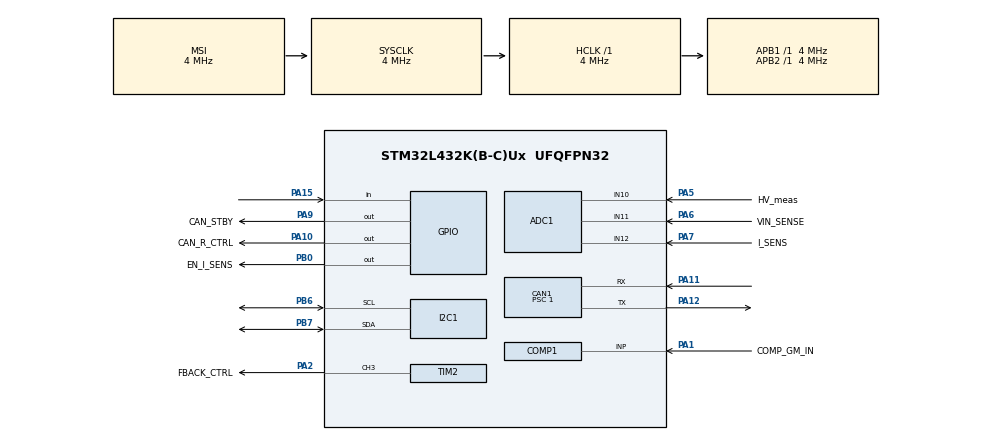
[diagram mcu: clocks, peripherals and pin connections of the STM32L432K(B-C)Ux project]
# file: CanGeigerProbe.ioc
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ADC1.Channel-0\#ChannelRegularConversion=ADC_CHANNEL_10
ADC1.Channel-1\#ChannelRegularConversion=ADC_CHANNEL_11
ADC1.Channel-2\#ChannelRegularConversion=ADC_CHANNEL_12
ADC1.Channel-3\#ChannelRegularConversion=ADC_CHANNEL_VREFINT
ADC1.Channel-4\#ChannelRegularConversion=ADC_CHANNEL_TEMPSENSOR
ADC1.NbrOfConversion=5
ADC1.NbrOfConversionFlag=1
ADC1.OffsetNumber-0\#ChannelRegularConversion=ADC_OFFSET_NONE
ADC1.OffsetNumber-1\#ChannelRegularConversion=ADC_OFFSET_NONE
ADC1.OffsetNumber-2\#ChannelRegularConversion=ADC_OFFSET_NONE
ADC1.OffsetNumber-3\#ChannelRegularConversion=ADC_OFFSET_NONE
ADC1.OffsetNumber-4\#ChannelRegularConversion=ADC_OFFSET_NONE
ADC1.OversamplingMode=ENABLE
ADC1.Rank-0\#ChannelRegularConversion=1
ADC1.Rank-1\#ChannelRegularConversion=2
ADC1.Rank-2\#ChannelRegularConversion=3
ADC1.Rank-3\#ChannelRegularConversion=4
ADC1.Rank-4\#ChannelRegularConversion=5
ADC1.Ratio=ADC_OVERSAMPLING_RATIO_16
ADC1.RightBitShift=ADC_RIGHTBITSHIFT_2
ADC1.SamplingTime-0\#ChannelRegularConversion=ADC_SAMPLETIME_247CYCLES_5
ADC1.SamplingTime-1\#ChannelRegularConversion=ADC_SAMPLETIME_640CYCLES_5
ADC1.SamplingTime-2\#ChannelRegularConversion=ADC_SAMPLETIME_247CYCLES_5
ADC1.SamplingTime-3\#ChannelRegularConversion=ADC_SAMPLETIME_640CYCLES_5
ADC1.SamplingTime-4\#ChannelRegularConversion=ADC_SAMPLETIME_640CYCLES_5
ADC1.master=1
CAN1.BS1=CAN_BS1_6TQ
CAN1.CalculateBaudRate=500000
CAN1.CalculateTimeBit=2000
CAN1.CalculateTimeQuantum=250.0
CAN1.NART=ENABLE
CAN1.Prescaler=1
CAN1.TXFP=ENABLE
COMP1.BlankingSrce=COMP_BLANKINGSRC_TIM2_OC3_COMP1
COMP1.Hysteresis=COMP_HYSTERESIS_MEDIUM
COMP1.Mode=COMP_POWERMODE_ULTRALOWPOWER
COMP1.OutputPol=COMP_OUTPUTPOL_INVERTED
Dma.ADC1.0.Direction=DMA_PERIPH_TO_MEMORY
Dma.ADC1.0.Instance=DMA1_Channel1
Dma.ADC1.0.MemDataAlignment=DMA_MDATAALIGN_HALFWORD
Dma.ADC1.0.MemInc=DMA_MINC_ENABLE
Dma.ADC1.0.Mode=DMA_NORMAL
Dma.ADC1.0.PeriphDataAlignment=DMA_PDATAALIGN_HALFWORD
Dma.ADC1.0.PeriphInc=DMA_PINC_DISABLE
Dma.ADC1.0.Priority=DMA_PRIORITY_LOW
Dma.I2C1_RX.3.Direction=DMA_PERIPH_TO_MEMORY
Dma.I2C1_RX.3.Instance=DMA1_Channel7
Dma.I2C1_RX.3.MemDataAlignment=DMA_MDATAALIGN_BYTE
Dma.I2C1_RX.3.MemInc=DMA_MINC_ENABLE
Dma.I2C1_RX.3.Mode=DMA_NORMAL
Dma.I2C1_RX.3.PeriphDataAlignment=DMA_PDATAALIGN_BYTE
Dma.I2C1_RX.3.PeriphInc=DMA_PINC_DISABLE
Dma.I2C1_RX.3.Priority=DMA_PRIORITY_LOW
Dma.I2C1_TX.2.Direction=DMA_MEMORY_TO_PERIPH
Dma.I2C1_TX.2.Instance=DMA1_Channel6
Dma.I2C1_TX.2.MemDataAlignment=DMA_MDATAALIGN_BYTE
Dma.I2C1_TX.2.MemInc=DMA_MINC_ENABLE
Dma.I2C1_TX.2.Mode=DMA_NORMAL
Dma.I2C1_TX.2.PeriphDataAlignment=DMA_PDATAALIGN_BYTE
Dma.I2C1_TX.2.PeriphInc=DMA_PINC_DISABLE
Dma.I2C1_TX.2.Priority=DMA_PRIORITY_LOW
Dma.Request0=ADC1
Dma.Request1=TIM2_UP
Dma.Request2=I2C1_TX
Dma.Request3=I2C1_RX
Dma.TIM2_UP.1.Direction=DMA_MEMORY_TO_PERIPH
Dma.TIM2_UP.1.Instance=DMA1_Channel2
Dma.TIM2_UP.1.MemDataAlignment=DMA_MDATAALIGN_WORD
Dma.TIM2_UP.1.MemInc=DMA_MINC_ENABLE
Dma.TIM2_UP.1.Mode=DMA_NORMAL
Dma.TIM2_UP.1.PeriphDataAlignment=DMA_PDATAALIGN_WORD
Dma.TIM2_UP.1.PeriphInc=DMA_PINC_DISABLE
Dma.TIM2_UP.1.Priority=DMA_PRIORITY_LOW
I2C1.Timing=0x00100D14
Mcu.Family=STM32L4
Mcu.Name=STM32L432K(B-C)Ux
Mcu.Package=UFQFPN32
NVIC.CAN1_RX0_IRQn=true\:0\:0\:false\:false\:true\:true\:true\:true
NVIC.CAN1_TX_IRQn=true\:0\:0\:false\:false\:true\:true\:true\:true
NVIC.DMA1_Channel1_IRQn=true\:0\:0\:false\:false\:true\:false\:true\:true
NVIC.DMA1_Channel2_IRQn=true\:0\:0\:false\:false\:true\:false\:true\:true
NVIC.DMA1_Channel6_IRQn=true\:0\:0\:false\:false\:true\:false\:true\:true
NVIC.DMA1_Channel7_IRQn=true\:0\:0\:false\:false\:true\:false\:true\:true
NVIC.I2C1_ER_IRQn=true\:0\:0\:false\:false\:true\:true\:true\:true
NVIC.I2C1_EV_IRQn=true\:0\:0\:false\:false\:true\:true\:true\:true
NVIC.LPTIM1_IRQn=true\:0\:0\:false\:false\:true\:true\:true\:true
NVIC.PriorityGroup=NVIC_PRIORITYGROUP_4
PA1.GPIO_Label=COMP_GM_IN
PA1.Mode=INP
PA1.Signal=COMP1_INP
PA10.GPIO_Label=CAN_R_CTRL
PA10.Signal=GPIO_Output
PA11.Mode=CAN_Activate
PA11.Signal=CAN1_RX
PA12.Mode=CAN_Activate
PA12.Signal=CAN1_TX
PA13\ (JTMS-SWDIO).GPIO_Label=SWDIO
PA13\ (JTMS-SWDIO).Mode=Trace_Asynchronous_SW
PA13\ (JTMS-SWDIO).Signal=SYS_JTMS-SWDIO
PA14\ (JTCK-SWCLK).GPIO_Label=SWCLK
PA14\ (JTCK-SWCLK).Mode=Trace_Asynchronous_SW
PA14\ (JTCK-SWCLK).Signal=SYS_JTCK-SWCLK
PA15\ (JTDI).Signal=GPIO_Input
PA2.GPIO_Label=FBACK_CTRL
PA2.GPIO_PuPd=GPIO_PULLDOWN
PA2.Signal=S_TIM2_CH3
PA5.GPIO_Label=HV_meas
PA5.Signal=ADCx_IN10
PA6.GPIO_Label=VIN_SENSE
PA6.Signal=ADCx_IN11
PA7.GPIO_Label=I_SENS
PA7.Signal=ADCx_IN12
PA9.GPIO_Label=CAN_STBY
PA9.Signal=GPIO_Output
PB0.GPIO_Label=EN_I_SENS
PB0.Signal=GPIO_Output
PB3\ (JTDO-TRACESWO).GPIO_Label=SWO
PB3\ (JTDO-TRACESWO).Mode=Trace_Asynchronous_SW
PB3\ (JTDO-TRACESWO).Signal=SYS_JTDO-SWO
PB6.Mode=I2C
PB6.Signal=I2C1_SCL
PB7.Mode=I2C
PB7.Signal=I2C1_SDA
ProjectManager.HeapSize=0x200
ProjectManager.StackSize=0x400
ProjectManager.TargetToolchain=STM32CubeIDE
RCC.ADCCLockSelection=RCC_ADCCLKSOURCE_SYSCLK
RCC.ADCFreq_Value=4000000
RCC.AHBFreq_Value=4000000
RCC.APB1Freq_Value=4000000
RCC.APB1TimFreq_Value=4000000
RCC.APB2Freq_Value=4000000
RCC.APB2TimFreq_Value=4000000
RCC.CortexFreq_Value=4000000
RCC.HCLKFreq_Value=4000000
RCC.HSE_VALUE=8000000
RCC.HSI48_VALUE=48000000
RCC.HSI_VALUE=16000000
RCC.LSE_VALUE=32768
RCC.MSI_VALUE=4000000
RCC.PLLSourceVirtual=RCC_PLLSOURCE_HSI
RCC.PWR_Regulator_Voltage_Scale=PWR_REGULATOR_VOLTAGE_SCALE2
RCC.SYSCLKFreq_VALUE=4000000
RCC.USBFreq_Value=64000000
RCC.VCOOutputFreq_Value=128000000
SH.ADCx_IN10.0=ADC1_IN10,IN10-Single-Ended
SH.ADCx_IN11.0=ADC1_IN11,IN11-Single-Ended
SH.ADCx_IN12.0=ADC1_IN12,IN12-Single-Ended
SH.S_TIM2_CH3.0=TIM2_CH3,PWM Generation3 CH3
TIM2.AutoReloadPreload=TIM_AUTORELOAD_PRELOAD_ENABLE
TIM2.Channel-PWM\ Generation3\ CH3=TIM_CHANNEL_3
VP_ADC1_TempSens_Input.Mode=IN-TempSens
VP_ADC1_Vref_Input.Mode=IN-Vrefint
VP_COMP1_VS_DACOUT1.Mode=INM_DACOUT1
VP_DAC1_VS_DACI1.Mode=DAC_OUT1_Int
VP_LPTIM1_VS_LPTIM_counterModeInternalClock.Mode=Counts__internal_clock_event_00
VP_TIM2_VS_ClockSourceINT.Mode=Internal
board=custom

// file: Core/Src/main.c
/* USER CODE BEGIN Header */
/**
  ******************************************************************************
  * @file           : main.c
  * @brief          : Main program body
  ******************************************************************************
  * @attention
  *
  * Copyright (c) 2026 STMicroelectronics.
  * All rights reserved.
  *
  * This software is licensed under terms that can be found in the LICENSE file
  * in the root directory of this software component.
  * If no LICENSE file comes with this software, it is provided AS-IS.
  *
  ******************************************************************************
  */
/* USER CODE END Header */
#include "main.h"

ADC_HandleTypeDef hadc1;
DMA_HandleTypeDef hdma_adc1;

CAN_HandleTypeDef hcan1;

COMP_HandleTypeDef hcomp1;

DAC_HandleTypeDef hdac1;

I2C_HandleTypeDef hi2c1;
DMA_HandleTypeDef hdma_i2c1_tx;
DMA_HandleTypeDef hdma_i2c1_rx;

LPTIM_HandleTypeDef hlptim1;

TIM_HandleTypeDef htim2;
DMA_HandleTypeDef hdma_tim2_up;

void SystemClock_Config(void);
static void MX_GPIO_Init(void);
static void MX_DMA_Init(void);
static void MX_ADC1_Init(void);
static void MX_CAN1_Init(void);
static void MX_COMP1_Init(void);
static void MX_DAC1_Init(void);
static void MX_I2C1_Init(void);
static void MX_TIM2_Init(void);
static void MX_LPTIM1_Init(void);

int main(void)
{

  /* USER CODE BEGIN 1 */
  /* Aplikacja jest zrelokowana za bootloaderem (0x08004000). Tablica wektorow
   * ustawiana przed HAL_Init, zanim wystartuja SysTick i przerwania. Tutaj,
   * a nie w system_stm32l4xx.c, zeby przetrwac regeneracje CubeMX. */
  SCB->VTOR = 0x08004000u;
  /* USER CODE END 1 */

  /* MCU Configuration--------------------------------------------------------*/

  /* Reset of all peripherals, Initializes the Flash interface and the Systick. */
  HAL_Init();

  /* Configure the system clock */
  SystemClock_Config();

  /* Initialize all configured peripherals */
  MX_GPIO_Init();
  MX_DMA_Init();
  MX_ADC1_Init();
  MX_CAN1_Init();
  MX_COMP1_Init();
  MX_DAC1_Init();
  MX_I2C1_Init();
  MX_TIM2_Init();
  MX_LPTIM1_Init();

  /* Infinite loop */
  while (1)
  {

  }
}

void SystemClock_Config(void)
{
  RCC_OscInitTypeDef RCC_OscInitStruct = {0};
  RCC_ClkInitTypeDef RCC_ClkInitStruct = {0};

  /** Configure the main internal regulator output voltage
  */
  if (HAL_PWREx_ControlVoltageScaling(PWR_REGULATOR_VOLTAGE_SCALE2) != HAL_OK)
  {
    Error_Handler();
  }

  /** Initializes the RCC Oscillators according to the specified parameters
  * in the RCC_OscInitTypeDef structure.
  */
  RCC_OscInitStruct.OscillatorType = RCC_OSCILLATORTYPE_MSI;
  RCC_OscInitStruct.MSIState = RCC_MSI_ON;
  RCC_OscInitStruct.MSICalibrationValue = 0;
  RCC_OscInitStruct.MSIClockRange = RCC_MSIRANGE_6;
  RCC_OscInitStruct.PLL.PLLState = RCC_PLL_NONE;
  if (HAL_RCC_OscConfig(&RCC_OscInitStruct) != HAL_OK)
  {
    Error_Handler();
  }

  /** Initializes the CPU, AHB and APB buses clocks
  */
  RCC_ClkInitStruct.ClockType = RCC_CLOCKTYPE_HCLK|RCC_CLOCKTYPE_SYSCLK
                              |RCC_CLOCKTYPE_PCLK1|RCC_CLOCKTYPE_PCLK2;
  RCC_ClkInitStruct.SYSCLKSource = RCC_SYSCLKSOURCE_MSI;
  RCC_ClkInitStruct.AHBCLKDivider = RCC_SYSCLK_DIV1;
  RCC_ClkInitStruct.APB1CLKDivider = RCC_HCLK_DIV1;
  RCC_ClkInitStruct.APB2CLKDivider = RCC_HCLK_DIV1;

  if (HAL_RCC_ClockConfig(&RCC_ClkInitStruct, FLASH_LATENCY_0) != HAL_OK)
  {
    Error_Handler();
  }
}

static void MX_ADC1_Init(void)
{

  ADC_ChannelConfTypeDef sConfig = {0};

  /** Common config
  */
  hadc1.Instance = ADC1;
  hadc1.Init.ClockPrescaler = ADC_CLOCK_ASYNC_DIV1;
  hadc1.Init.Resolution = ADC_RESOLUTION_12B;
  hadc1.Init.DataAlign = ADC_DATAALIGN_RIGHT;
  hadc1.Init.ScanConvMode = ADC_SCAN_ENABLE;
  hadc1.Init.EOCSelection = ADC_EOC_SINGLE_CONV;
  hadc1.Init.LowPowerAutoWait = DISABLE;
  hadc1.Init.ContinuousConvMode = DISABLE;
  hadc1.Init.NbrOfConversion = 5;
  hadc1.Init.DiscontinuousConvMode = DISABLE;
  hadc1.Init.ExternalTrigConv = ADC_SOFTWARE_START;
  hadc1.Init.ExternalTrigConvEdge = ADC_EXTERNALTRIGCONVEDGE_NONE;
  hadc1.Init.DMAContinuousRequests = DISABLE;
  hadc1.Init.Overrun = ADC_OVR_DATA_PRESERVED;
  hadc1.Init.OversamplingMode = ENABLE;
  hadc1.Init.Oversampling.Ratio = ADC_OVERSAMPLING_RATIO_16;
  hadc1.Init.Oversampling.RightBitShift = ADC_RIGHTBITSHIFT_2;
  hadc1.Init.Oversampling.TriggeredMode = ADC_TRIGGEREDMODE_SINGLE_TRIGGER;
  hadc1.Init.Oversampling.OversamplingStopReset = ADC_REGOVERSAMPLING_CONTINUED_MODE;
  if (HAL_ADC_Init(&hadc1) != HAL_OK)
  {
    Error_Handler();
  }

  /** Configure Regular Channel
  */
  sConfig.Channel = ADC_CHANNEL_10;
  sConfig.Rank = ADC_REGULAR_RANK_1;
  sConfig.SamplingTime = ADC_SAMPLETIME_247CYCLES_5;
  sConfig.SingleDiff = ADC_SINGLE_ENDED;
  sConfig.OffsetNumber = ADC_OFFSET_NONE;
  sConfig.Offset = 0;
  if (HAL_ADC_ConfigChannel(&hadc1, &sConfig) != HAL_OK)
  {
    Error_Handler();
  }

  /** Configure Regular Channel
  */
  sConfig.Channel = ADC_CHANNEL_11;
  sConfig.Rank = ADC_REGULAR_RANK_2;
  sConfig.SamplingTime = ADC_SAMPLETIME_640CYCLES_5;
  if (HAL_ADC_ConfigChannel(&hadc1, &sConfig) != HAL_OK)
  {
    Error_Handler();
  }

  /** Configure Regular Channel
  */
  sConfig.Channel = ADC_CHANNEL_12;
  sConfig.Rank = ADC_REGULAR_RANK_3;
  sConfig.SamplingTime = ADC_SAMPLETIME_247CYCLES_5;
  if (HAL_ADC_ConfigChannel(&hadc1, &sConfig) != HAL_OK)
  {
    Error_Handler();
  }

  /** Configure Regular Channel
  */
  sConfig.Channel = ADC_CHANNEL_VREFINT;
  sConfig.Rank = ADC_REGULAR_RANK_4;
  sConfig.SamplingTime = ADC_SAMPLETIME_640CYCLES_5;
  if (HAL_ADC_ConfigChannel(&hadc1, &sConfig) != HAL_OK)
  {
    Error_Handler();
  }

  /** Configure Regular Channel
  */
  sConfig.Channel = ADC_CHANNEL_TEMPSENSOR;
  sConfig.Rank = ADC_REGULAR_RANK_5;
  if (HAL_ADC_ConfigChannel(&hadc1, &sConfig) != HAL_OK)
  {
    Error_Handler();
  }

}

static void MX_CAN1_Init(void)
{

  hcan1.Instance = CAN1;
  hcan1.Init.Prescaler = 1;
  hcan1.Init.Mode = CAN_MODE_NORMAL;
  hcan1.Init.SyncJumpWidth = CAN_SJW_1TQ;
  hcan1.Init.TimeSeg1 = CAN_BS1_6TQ;
  hcan1.Init.TimeSeg2 = CAN_BS2_1TQ;
  hcan1.Init.TimeTriggeredMode = DISABLE;
  hcan1.Init.AutoBusOff = DISABLE;
  hcan1.Init.AutoWakeUp = DISABLE;
  hcan1.Init.AutoRetransmission = ENABLE;
  hcan1.Init.ReceiveFifoLocked = DISABLE;
  hcan1.Init.TransmitFifoPriority = ENABLE;
  if (HAL_CAN_Init(&hcan1) != HAL_OK)
  {
    Error_Handler();
  }

}

static void MX_COMP1_Init(void)
{

  hcomp1.Instance = COMP1;
  hcomp1.Init.InvertingInput = COMP_INPUT_MINUS_DAC1_CH1;
  hcomp1.Init.NonInvertingInput = COMP_INPUT_PLUS_IO3;
  hcomp1.Init.OutputPol = COMP_OUTPUTPOL_INVERTED;
  hcomp1.Init.Hysteresis = COMP_HYSTERESIS_MEDIUM;
  hcomp1.Init.BlankingSrce = COMP_BLANKINGSRC_TIM2_OC3_COMP1;
  hcomp1.Init.Mode = COMP_POWERMODE_ULTRALOWPOWER;
  hcomp1.Init.WindowMode = COMP_WINDOWMODE_DISABLE;
  hcomp1.Init.TriggerMode = COMP_TRIGGERMODE_NONE;
  if (HAL_COMP_Init(&hcomp1) != HAL_OK)
  {
    Error_Handler();
  }

}

static void MX_DAC1_Init(void)
{

  DAC_ChannelConfTypeDef sConfig = {0};

  /** DAC Initialization
  */
  hdac1.Instance = DAC1;
  if (HAL_DAC_Init(&hdac1) != HAL_OK)
  {
    Error_Handler();
  }

  /** DAC channel OUT1 config
  */
  sConfig.DAC_SampleAndHold = DAC_SAMPLEANDHOLD_DISABLE;
  sConfig.DAC_Trigger = DAC_TRIGGER_NONE;
  sConfig.DAC_OutputBuffer = DAC_OUTPUTBUFFER_DISABLE;
  sConfig.DAC_ConnectOnChipPeripheral = DAC_CHIPCONNECT_ENABLE;
  sConfig.DAC_UserTrimming = DAC_TRIMMING_FACTORY;
  if (HAL_DAC_ConfigChannel(&hdac1, &sConfig, DAC_CHANNEL_1) != HAL_OK)
  {
    Error_Handler();
  }

}

static void MX_I2C1_Init(void)
{

  hi2c1.Instance = I2C1;
  hi2c1.Init.Timing = 0x00100D14;
  hi2c1.Init.OwnAddress1 = 0;
  hi2c1.Init.AddressingMode = I2C_ADDRESSINGMODE_7BIT;
  hi2c1.Init.DualAddressMode = I2C_DUALADDRESS_DISABLE;
  hi2c1.Init.OwnAddress2 = 0;
  hi2c1.Init.OwnAddress2Masks = I2C_OA2_NOMASK;
  hi2c1.Init.GeneralCallMode = I2C_GENERALCALL_DISABLE;
  hi2c1.Init.NoStretchMode = I2C_NOSTRETCH_DISABLE;
  if (HAL_I2C_Init(&hi2c1) != HAL_OK)
  {
    Error_Handler();
  }

  /** Configure Analogue filter
  */
  if (HAL_I2CEx_ConfigAnalogFilter(&hi2c1, I2C_ANALOGFILTER_ENABLE) != HAL_OK)
  {
    Error_Handler();
  }

  /** Configure Digital filter
  */
  if (HAL_I2CEx_ConfigDigitalFilter(&hi2c1, 0) != HAL_OK)
  {
    Error_Handler();
  }

}

static void MX_LPTIM1_Init(void)
{

  hlptim1.Instance = LPTIM1;
  hlptim1.Init.Clock.Source = LPTIM_CLOCKSOURCE_APBCLOCK_LPOSC;
  hlptim1.Init.Clock.Prescaler = LPTIM_PRESCALER_DIV1;
  hlptim1.Init.Trigger.Source = LPTIM_TRIGSOURCE_SOFTWARE;
  hlptim1.Init.OutputPolarity = LPTIM_OUTPUTPOLARITY_HIGH;
  hlptim1.Init.UpdateMode = LPTIM_UPDATE_IMMEDIATE;
  hlptim1.Init.CounterSource = LPTIM_COUNTERSOURCE_INTERNAL;
  hlptim1.Init.Input1Source = LPTIM_INPUT1SOURCE_GPIO;
  hlptim1.Init.Input2Source = LPTIM_INPUT2SOURCE_GPIO;
  if (HAL_LPTIM_Init(&hlptim1) != HAL_OK)
  {
    Error_Handler();
  }
  /* USER CODE BEGIN LPTIM1_Init 2 */
  /* Tor zliczania impulsow tuby: COMP1 -> LPTIM1 Input1. CubeMX w trybie
   * "Counts internal clock events" nie udostepnia wyboru wejscia, a tryb
   * "external" zajmuje pin LPTIM1_IN1 (PB5). Licznik zlicza zbocza narastajace
   * wyjscia COMP1 probkowane zegarem PCLK; filtr 8 taktow (2 us przy 4 MHz)
   * odrzuca zaklocenia krotsze niz impuls z tuby. Licznik startuje dopiero
   * z modulu zliczania (ARR 0xFFFF, przerwanie ARRM rozszerza go do 32 bitow). */
  hlptim1.Init.CounterSource = LPTIM_COUNTERSOURCE_EXTERNAL;
  hlptim1.Init.Input1Source = LPTIM_INPUT1SOURCE_COMP1;
  hlptim1.Init.UltraLowPowerClock.Polarity = LPTIM_CLOCKPOLARITY_RISING;
  hlptim1.Init.UltraLowPowerClock.SampleTime = LPTIM_CLOCKSAMPLETIME_8TRANSITIONS;
  if (HAL_LPTIM_Init(&hlptim1) != HAL_OK)
  {
    Error_Handler();
  }
  /* USER CODE END LPTIM1_Init 2 */

}

static void MX_TIM2_Init(void)
{

  TIM_ClockConfigTypeDef sClockSourceConfig = {0};
  TIM_MasterConfigTypeDef sMasterConfig = {0};
  TIM_OC_InitTypeDef sConfigOC = {0};

  htim2.Instance = TIM2;
  htim2.Init.Prescaler = 0;
  htim2.Init.CounterMode = TIM_COUNTERMODE_UP;
  htim2.Init.Period = 4294967295;
  htim2.Init.ClockDivision = TIM_CLOCKDIVISION_DIV1;
  htim2.Init.AutoReloadPreload = TIM_AUTORELOAD_PRELOAD_ENABLE;
  if (HAL_TIM_Base_Init(&htim2) != HAL_OK)
  {
    Error_Handler();
  }
  sClockSourceConfig.ClockSource = TIM_CLOCKSOURCE_INTERNAL;
  if (HAL_TIM_ConfigClockSource(&htim2, &sClockSourceConfig) != HAL_OK)
  {
    Error_Handler();
  }
  if (HAL_TIM_PWM_Init(&htim2) != HAL_OK)
  {
    Error_Handler();
  }
  sMasterConfig.MasterOutputTrigger = TIM_TRGO_RESET;
  sMasterConfig.MasterSlaveMode = TIM_MASTERSLAVEMODE_DISABLE;
  if (HAL_TIMEx_MasterConfigSynchronization(&htim2, &sMasterConfig) != HAL_OK)
  {
    Error_Handler();
  }
  sConfigOC.OCMode = TIM_OCMODE_PWM1;
  sConfigOC.Pulse = 0;
  sConfigOC.OCPolarity = TIM_OCPOLARITY_HIGH;
  sConfigOC.OCFastMode = TIM_OCFAST_DISABLE;
  if (HAL_TIM_PWM_ConfigChannel(&htim2, &sConfigOC, TIM_CHANNEL_3) != HAL_OK)
  {
    Error_Handler();
  }
  HAL_TIM_MspPostInit(&htim2);

}

static void MX_DMA_Init(void)
{

  /* DMA controller clock enable */
  __HAL_RCC_DMA1_CLK_ENABLE();

  /* DMA interrupt init */
  /* DMA1_Channel1_IRQn interrupt configuration */
  HAL_NVIC_SetPriority(DMA1_Channel1_IRQn, 0, 0);
  HAL_NVIC_EnableIRQ(DMA1_Channel1_IRQn);
  /* DMA1_Channel2_IRQn interrupt configuration */
  HAL_NVIC_SetPriority(DMA1_Channel2_IRQn, 0, 0);
  HAL_NVIC_EnableIRQ(DMA1_Channel2_IRQn);
  /* DMA1_Channel6_IRQn interrupt configuration */
  HAL_NVIC_SetPriority(DMA1_Channel6_IRQn, 0, 0);
  HAL_NVIC_EnableIRQ(DMA1_Channel6_IRQn);
  /* DMA1_Channel7_IRQn interrupt configuration */
  HAL_NVIC_SetPriority(DMA1_Channel7_IRQn, 0, 0);
  HAL_NVIC_EnableIRQ(DMA1_Channel7_IRQn);

}

static void MX_GPIO_Init(void)
{
  GPIO_InitTypeDef GPIO_InitStruct = {0};

  /* GPIO Ports Clock Enable */
  __HAL_RCC_GPIOC_CLK_ENABLE();
  __HAL_RCC_GPIOA_CLK_ENABLE();
  __HAL_RCC_GPIOB_CLK_ENABLE();

  /*Configure GPIO pin Output Level */
  HAL_GPIO_WritePin(EN_I_SENS_GPIO_Port, EN_I_SENS_Pin, GPIO_PIN_RESET);

  /*Configure GPIO pin Output Level */
  HAL_GPIO_WritePin(GPIOA, CAN_STBY_Pin|CAN_R_CTRL_Pin, GPIO_PIN_RESET);

  /*Configure GPIO pin : PC14 */
  GPIO_InitStruct.Pin = GPIO_PIN_14;
  GPIO_InitStruct.Mode = GPIO_MODE_ANALOG;
  GPIO_InitStruct.Pull = GPIO_NOPULL;
  HAL_GPIO_Init(GPIOC, &GPIO_InitStruct);

  /*Configure GPIO pin : EN_I_SENS_Pin */
  GPIO_InitStruct.Pin = EN_I_SENS_Pin;
  GPIO_InitStruct.Mode = GPIO_MODE_OUTPUT_PP;
  GPIO_InitStruct.Pull = GPIO_NOPULL;
  GPIO_InitStruct.Speed = GPIO_SPEED_FREQ_LOW;
  HAL_GPIO_Init(EN_I_SENS_GPIO_Port, &GPIO_InitStruct);

  /*Configure GPIO pins : CAN_STBY_Pin CAN_R_CTRL_Pin */
  GPIO_InitStruct.Pin = CAN_STBY_Pin|CAN_R_CTRL_Pin;
  GPIO_InitStruct.Mode = GPIO_MODE_OUTPUT_PP;
  GPIO_InitStruct.Pull = GPIO_NOPULL;
  GPIO_InitStruct.Speed = GPIO_SPEED_FREQ_LOW;
  HAL_GPIO_Init(GPIOA, &GPIO_InitStruct);

  /*Configure GPIO pin : PA15 */
  GPIO_InitStruct.Pin = GPIO_PIN_15;
  GPIO_InitStruct.Mode = GPIO_MODE_INPUT;
  GPIO_InitStruct.Pull = GPIO_NOPULL;
  HAL_GPIO_Init(GPIOA, &GPIO_InitStruct);

}

void Error_Handler(void)
{
  __disable_irq();
  while (1)
  {
  }
}
